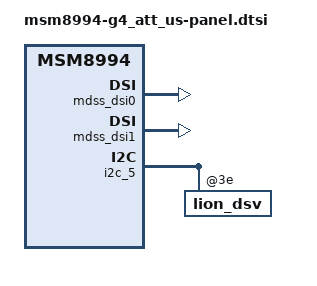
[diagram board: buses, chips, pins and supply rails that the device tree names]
/* Copyright (c) 2014, The Linux Foundation. All rights reserved.
 *
 * This program is free software; you can redistribute it and/or modify
 * it under the terms of the GNU General Public License version 2 and
 * only version 2 as published by the Free Software Foundation.
 *
 * This program is distributed in the hope that it will be useful,
 * but WITHOUT ANY WARRANTY; without even the implied warranty of
 * MERCHANTABILITY or FITNESS FOR A PARTICULAR PURPOSE.  See the
 * GNU General Public License for more details.
 */

#include "../msm8994-g4_common/msm8994-common-panel.dtsi"

//copy from msm8994-cdp.dtsi and modify.


&mdss_mdp {

};

&pmx_mdss {

};

&mdss_dsi0 {
	status = "ok";

};

&mdss_fb0 {

};

&mdss_dsi1 {
	status = "ok";

};

&dsi_dual_jdi_cmd_0{

};

/* RPM controlled regulators: */

&rpm_bus {

};
&i2c_5 {
    lion_dsv@3e {
        status = "ok";

    };
};
